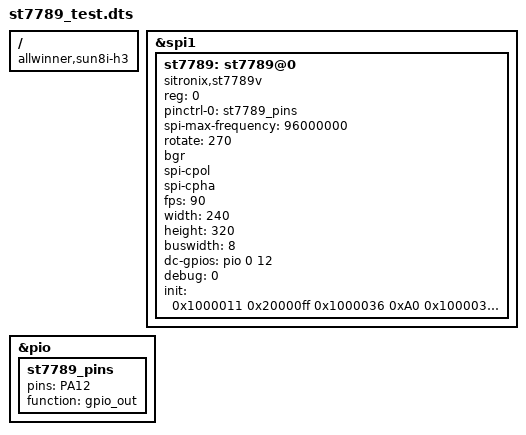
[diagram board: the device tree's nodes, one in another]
/dts-v1/;
/plugin/;

/ {
    compatible = "allwinner,sun8i-h3";
    fragment@0 {
        target = <&spi1>;
        __overlay__ {
            status = "okay";
            #address-cells = <1>;
            #size-cells = <0>;
            st7789: st7789@0{
                compatible = "sitronix,st7789v";
                reg = <0>;
                pinctrl-names = "default";
                pinctrl-0 = <&st7789_pins>;
                spi-max-frequency = <96000000>;
                rotate = <270>;
                bgr;
                spi-cpol;
                spi-cpha;
                fps = <90>;
                width= <240>;
                height= <320>;
                buswidth = <8>;
                dc-gpios = <&pio 0 12 0>;
                debug = <0>;
                init = <0x1000011
                        0x20000ff
                        0x1000036 0xA0
                        0x100003a 0x05
                        0x1000021
                        0x100002a 0x00 0x01 0x00 0x3f
                        0x100002b 0x00 0x00 0x00 0xef
                        0x10000b2 0x0c 0x0c 0x00 0x33 0x33
                        0x10000b7 0x35
                        0x10000bb 0x1f
                        0x10000c0 0x0c
                        0x10000c2 0x01
                        0x10000c3 0x12
                        0x10000c4 0x20
                        0x10000c6 0x0f
                        0x10000d0 0xa4 0xa1
                        0x10000e0 0xd0 0x08 0x11 0x08 0x0C 0x15 0x39 0x33 0x50 0x36 0x13 0x14 0x29 0x2d
                        0x10000e1 0xd0 0x08 0x10 0x08 0x06 0x06 0x39 0x44 0x51 0x0b 0x16 0x14 0x2f 0x31
                        0x1000029>;
            };
        };
    };

    fragment@1 {
        target = <&pio>;
        __overlay__ {
            st7789_pins: st7789_pins {
                pins = "PA12";
                function = "gpio_out";
            };
        };
    };
};
